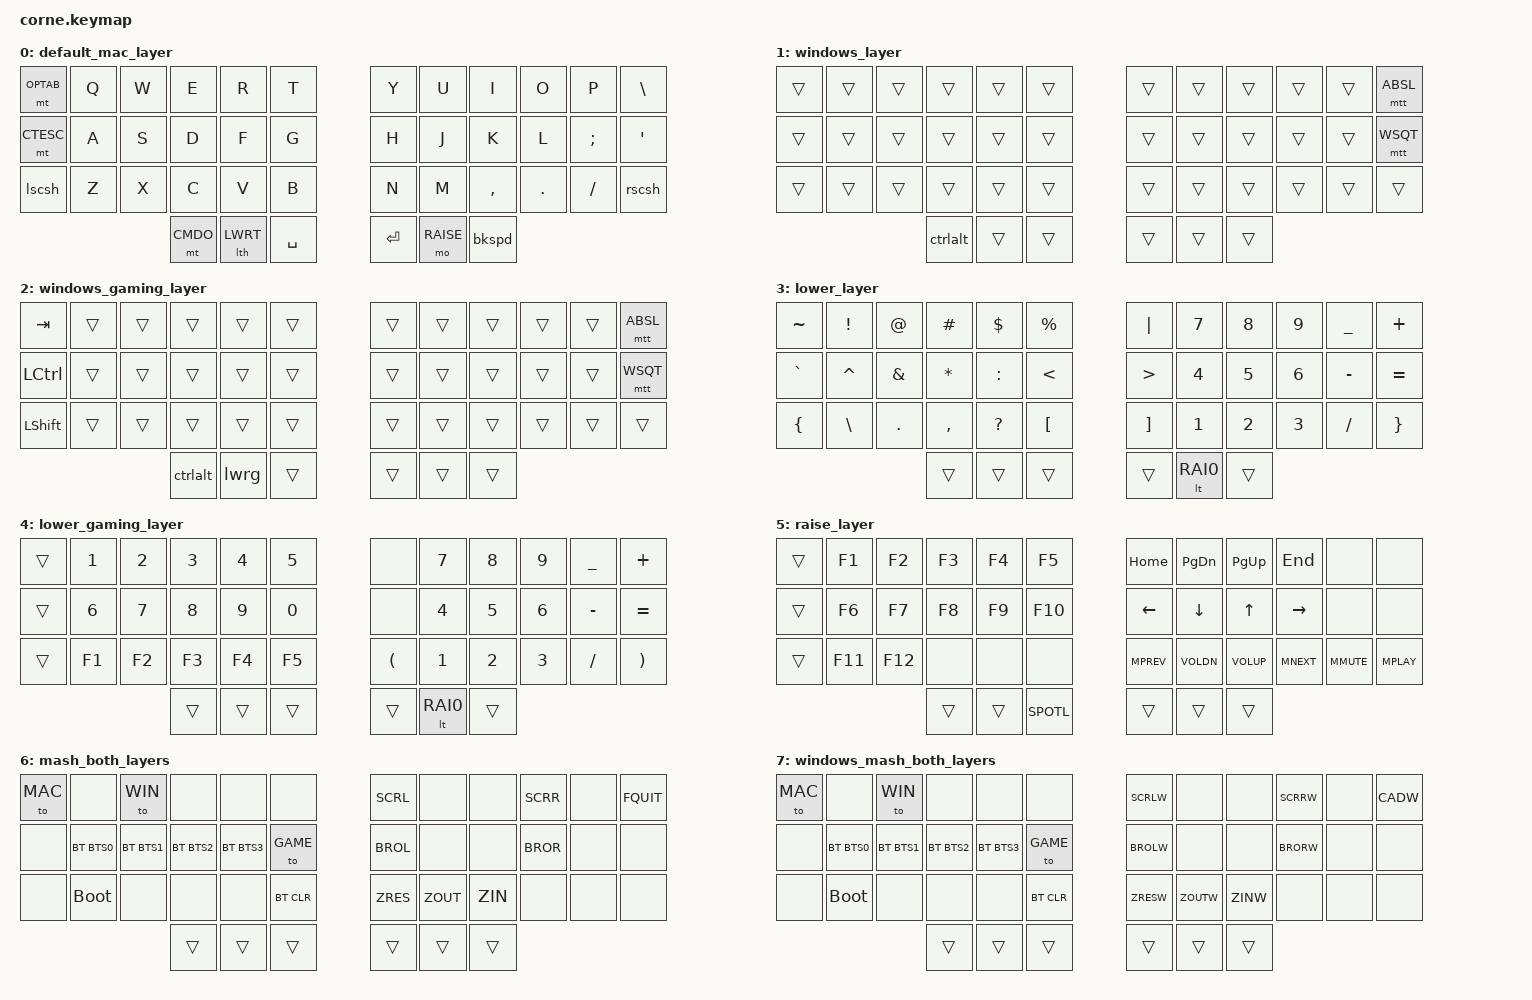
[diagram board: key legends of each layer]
#include <behaviors.dtsi>
#include <dt-bindings/zmk/keys.h>
#include <dt-bindings/zmk/bt.h>

// Layers
#define MAC 0
#define WIN 1
#define GAME 2
#define LOWER 3
#define GAME_LOWER 4
#define RAISE 5
#define MASH 6
#define WIN_MASH 7

// Aliases
#define OPTAB LALT TAB       // Mod-Tap shorthand for OPTION when held, TAB when tapped
#define CTESC LCTRL ESC      // Mod-Tap shorthand for CTRL when held, ESC when tapped
#define LWRT  LOWER F13      // Hold for lower layer, tap for app launcher modal
#define CMDO  LGUI F14       // Hold for cmd, tap for macros modal
#define RAI0  RAISE N0       // Mod-Tap shorthand for RAISE layer when held, or numpad 0 when typed
#define SPOTL LG(SPACE)      // Key-Press shorthand for CMD-SPACE Spotlight / Raycast / etc. search
#define MPREV C_PREV         // Key-Press shorthand for PREV media key
#define MNEXT C_NEXT         // Key-Press shorthand for NEXT media key
#define VOLUP C_VOL_UP       // Key-Press shorthand for VOLUME UP media key
#define VOLDN C_VOL_DN       // Key-Press shorthand for VOLUME DOWN media key
#define MPLAY C_PP           // Key-Press shorthand for PLAY / PAUSE media key
#define MMUTE C_MUTE         // Key-Press shorthand for MUTE media key
#define SCRL  LC(LEFT)       // Key-Press shorthand for Mission control space left
#define SCRR  LC(RIGHT)      // Key-Press shorthand for Mission control space right
#define BROL  LG(LA(LEFT))   // Key-Press shorthand for browser tab left
#define BROR  LG(LA(RIGHT))  // Key-Press shorthand for browser tab right
#define ZIN   LG(EQUAL)      // Key-Press shorthand for zoom in
#define ZOUT  LG(MINUS)      // Key-Press shorthand for zoom out
#define ZRES  LG(N0)         // Key-Press shorthand for zoom reset
#define FQUIT LG(LA(ESC))    // Key-Press shorthand for force quit applications dialog
#define BTS0  BT_SEL 0       // Select Bluetooth profile 0
#define BTS1  BT_SEL 1       // Select Bluetooth profile 1
#define BTS2  BT_SEL 2       // Select Bluetooth profile 2
#define BTS3  BT_SEL 3       // Select Bluetooth profile 3

// Windows Specific Aliases
#define ABSL  LALT BSLH      // Mod-Tap shorthand for ALT when held, BSLH when tapped
#define WSQT  LGUI SQT       // Mod-Tap shorthand for WIN when held, SQT when tapped
#define SCRLW LG(LC(LEFT))   // Key-Press shorthand for virtual desktop left in Windows
#define SCRRW LG(LC(RIGHT))  // Key-Press shorthand for virtual desktop right in Windows
#define BROLW LC(LS(TAB))    // Key-Press shorthand for browser tab left in Windows
#define BRORW LC(TAB)        // Key-Press shorthand for browser tab right in Windows
#define ZINW  LC(EQUAL)      // Key-Press shorthand for zoom in Windows
#define ZOUTW LC(MINUS)      // Key-Press shorthand for zoom out in Windows
#define ZRESW LC(N0)         // Key-Press shorthand for zoom reset in Windows
#define CADW  LC(LA(DEL))    // Key-Press shorthand for CTRL-ALT-DEL in Windows

/ {

    keymap {
        compatible = "zmk,keymap";

        default_mac_layer {
            bindings = <
            // +----------+----------+----------+----------+----------+----------+     +----------+----------+----------+----------+--[ COMBO FOR DEL ]--+
            //   OPT TAB    Q          W          E          R          T                Y          U          I          O          P          \ |
                 &mt OPTAB  &kp Q      &kp W      &kp E      &kp R      &kp T            &kp Y      &kp U      &kp I      &kp O      &kp P      &kp BSLH
            // +----------+----------+--[ HYPER + BIG HYPER COMBOS ]--+----------+     +----------+----------+----------+----------+----------+----------+
            //   CTRL ESC   A          S          D          F          G                H          J          K          L          ; :        ' "
                 &mt CTESC  &kp A      &kp S      &kp D      &kp F      &kp G            &kp H      &kp J      &kp K      &kp L      &kp SEMI   &kp SQT
            // +----------+----------+----------+----------+----------+----------+     +----------+----------+----------+----------+----------+----------+
            //   SHIFT (    Z          X          C          V          B                N          M          , <        . >        / ?        SHIFT )
                 &lscsh     &kp Z      &kp X      &kp C      &kp V      &kp B            &kp N      &kp M      &kp COMMA  &kp DOT    &kp FSLH   &rscsh
            // +----------+----------+----------+----------+----------+----------+     +----------+----------+----------+----------+----------+----------+
            //                                    CMD        LOWER      SPACE            ENTER      RAISE      BKSP DEL
                                                  &mt CMDO   &lth LWRT  &kp SPACE        &kp ENTER  &mo RAISE  &bkspd
            //                                  +----------+----------+----------+     +----------+----------+----------+
            //
            // * Notes:
            //   - In standard CAPS key position, hold for CTRL, or tap for ESC
            //   - In standard TAB key position, hold for OPT, or tap for TAB
            //   - In standard SHIFT key positions, hold for SHIFT, or tap for open `(` and close `)` parentheses (left and right respectively)
            //   - Combo D+F keys for HYPER (CTRL+OPT+CMD)
            //   - Combo S+D+F keys for BIG HYPER (SHIFT+CTRL+OPT+CMD)
            //   - Combo P+\ in top right corner for forward DEL
            //   - Shift backspace for forward delete
            //   - See other layers for more:
            //     - LOWER layer for symbols, numpad, summon apps function, summon terminal function, run macros function, etc.
            //     - RAISE layer for hjkl arrows, page navigation keys, media keys, function keys, spotlight search, etc.
            //     - MASH layer (LOWER+RAISE) for default layer toggling, screen switching, browser tab switching, zoom helpers, etc.
            >;
        };

        windows_layer {
            bindings = <
            // +----------+----------+----------+----------+----------+----------+     +----------+----------+----------+----------+---------------------+
            //                                                                                                                                  ALT \ |
                 &trans     &trans     &trans     &trans     &trans     &trans           &trans     &trans     &trans     &trans     &trans     &mtt ABSL
            // +----------+----------+----------+----------+----------+----------+     +----------+----------+----------+----------+---------------------+
            //                                                                                                                                  WIN ' "
                 &trans     &trans     &trans     &trans     &trans     &trans           &trans     &trans     &trans     &trans     &trans     &mtt WSQT
            // +----------+----------+----------+----------+----------+----------+     +----------+----------+----------+----------+----------+----------+
            //
                 &trans     &trans     &trans     &trans     &trans     &trans           &trans     &trans     &trans     &trans     &trans     &trans
            // +----------+----------+----------+----------+----------+----------+     +----------+----------+----------+----------+----------+----------+
            //                                    CTRL TAP
                                                  &ctrlalt   &trans     &trans           &trans     &trans     &trans
            //                                  +----------+----------+----------+     +----------+----------+----------+
            //
            // * Differences from above default Mac layer:
            //   - CTRL instead of CMD on thumb for easy copy/paste/etc. in Windows
            //   - CTRL thumb tap-dance for easy access to ALT, when right hand is on mouse
            //     - Tap once for CTRL
            //     - Tap twice for ALT
            //   - In standard backslash position, hold for ALT, or tap for `\`
            //   - In standard quote position, hold for WIN, or tap for `'`
            >;
        };

        windows_gaming_layer {
            bindings = <
            // +--[ COMBO FOR ESC ]--+----------+----------+----------+----------+     +----------+----------+----------+----------+---------------------+
            //   TAB                                                                                                                            ALT \ |
                 &kp TAB    &trans     &trans     &trans     &trans     &trans           &trans     &trans     &trans     &trans     &trans     &mtt ABSL
            // +----------+----------+----------+----------+----------+----------+     +----------+----------+----------+----------+---------------------+
            //   CTRL                                                                                                                           WIN ' "
                 &kp LCTRL  &trans     &trans     &trans     &trans     &trans           &trans     &trans     &trans     &trans     &trans     &mtt WSQT
            // +----------+----------+----------+----------+----------+----------+     +----------+----------+----------+----------+----------+----------+
            //   SHIFT
                 &kp LSHFT  &trans     &trans     &trans     &trans     &trans           &trans     &trans     &trans     &trans     &trans     &trans
            // +----------+----------+----------+----------+----------+----------+     +----------+----------+----------+----------+----------+----------+
            //                                    CTRL TAP   LOWER GAMING
                                                  &ctrlalt   &lwrg       &trans           &trans     &trans     &trans
            //                                  +----------+----------+----------+     +----------+----------+----------+
            //
            // * Differences from default Windows layer:
            //   - Combo TAB+Q in top left corner for easy access to ESC while gaming
            //   - Remove mod-tap and space cadet shift magic in left-most column, so that they don't interfere with gaming
            //   - See other layers for more:
            //     - Lower layer is customized for gaming, with access to numbers and function keys on left split
            //     - Touble tap and hold for access to normal symbols lower layer
            >;
        };

        lower_layer {
            bindings = <
            // +----------+----------+----------+----------+----------+----------+     +----------+----------+----------+----------+----------+----------+
            //   ~          !          @          #          $          %                |          7          8          9          _          +
                 &kp TILDE  &kp EXCL   &kp AT     &kp HASH   &kp DLLR   &kp PRCNT        &kp PIPE   &kp N7     &kp N8     &kp N9     &kp UNDER  &kp PLUS
            // +----------+----------+----------+----------+----------+----------+     +----------+----------+----------+----------+----------+----------+
            //   `          ^          &          *          :          <                >          4          5          6          -          =
                 &kp GRAVE  &kp CARET  &kp AMPS   &kp ASTRK  &kp COLON  &kp LT           &kp GT     &kp N4     &kp N5     &kp N6     &kp MINUS  &kp EQUAL
            // +----------+----------+----------+----------+----------+----------+     +----------+----------+----------+----------+----------+----------+
            //   {          \          .          ,          ?          [                ]          1          2          3          /          }
                 &kp LBRC   &kp BSLH   &kp DOT    &kp COMMA  &kp QMARK  &kp LBKT         &kp RBKT   &kp N1     &kp N2     &kp N3     &kp FSLH   &kp RBRC
            // +----------+----------+----------+----------+----------+----------+     +----------+----------+----------+----------+----------+----------+
            //                                                                                      0 RAISE
                                                  &trans     &trans     &trans           &trans     &lt RAI0   &trans
            //                                  +----------+----------+----------+     +----------+----------+----------+
            //
            // * Notes:
            //   - Almost all symbols accessible on this layer
            //   - Numpad under right hand
            >;
        };

        lower_gaming_layer {
            bindings = <
            // +----------+----------+----------+----------+----------+----------+     +----------+----------+----------+----------+----------+----------+
            //              1          2          3          4          5                           7          8          9          _          +
                 &trans     &kp N1     &kp N2     &kp N3     &kp N4     &kp N5           &none      &kp N7     &kp N8     &kp N9     &kp UNDER  &kp PLUS
            // +----------+----------+----------+----------+----------+----------+    +----------+----------+----------+----------+----------+----------+
            //              6          7          8          9          0                           4          5          6          -          =
                 &trans     &kp N6     &kp N7     &kp N8     &kp N9     &kp N0           &none      &kp N4     &kp N5     &kp N6     &kp MINUS  &kp EQUAL
            // +----------+----------+----------+----------+----------+----------+     +----------+----------+----------+----------+----------+----------+
            //              F1         F2         F3         F4         F5               (          1          2          3          /          )
                 &trans     &kp F1     &kp F2     &kp F3     &kp F4     &kp F5           &kp LPAR   &kp N1     &kp N2     &kp N3     &kp FSLH   &kp RPAR
            // +----------+----------+----------+----------+----------+----------+     +----------+----------+----------+----------+----------+----------+
            //                                                                                      0 RAISE
                                                  &trans     &trans     &trans           &trans     &lt RAI0   &trans
            //                                  +----------+----------+----------+     +----------+----------+----------+
            //
            // * Notes:
            //     - Basically same as standard lower layer, but with access to numbers and function keys on left split
            //       - But I left numpad on right split, since it doesn't hurt anybody to be there
            //     - For typing normal symbols layer while gaming, double tap and hold lower layer thumb
            //       - Though I moved left opening `(` paren to right split, since it's nowhere to be found on standard symbols layer
            >;
        };

        raise_layer {
            bindings = <
            // +----------+----------+----------+----------+----------+----------+     +----------+----------+----------+----------+----------+----------+
            //              FUNCTION KEYS 1-5                                            PAGE NAVIGATION
                 &trans     &kp F1     &kp F2     &kp F3     &kp F4     &kp F5           &kp HOME   &kp PG_DN  &kp PG_UP  &kp END    &none      &none
            // +----------+----------+----------+----------+----------+----------+     +----------+----------+----------+----------+----------+----------+
            //              FUNCTION KEYS 6-10                                           HJKL ARROW KEYS
                 &trans     &kp F6     &kp F7     &kp F8     &kp F9     &kp F10          &kp LEFT   &kp DOWN   &kp UP     &kp RIGHT  &none      &none
            // +----------+----------+----------+----------+----------+----------+     +----------+----------+----------+----------+----------+----------+
            //              FUNCTION KEYS 11-12                                          MEDIA KEYS
                 &trans     &kp F11    &kp F12    &none      &none      &none            &kp MPREV  &kp VOLDN  &kp VOLUP  &kp MNEXT  &kp MMUTE  &kp MPLAY
            // +----------+----------+----------+----------+----------+----------+     +----------+----------+----------+----------+----------+----------+
            //                                                          SEARCH
                                                  &trans     &trans     &kp SPOTL        &trans     &trans     &trans
            //                                  +----------+----------+----------+     +----------+----------+----------+
            //
            // * Notes:
            //   - Arrow keys in HJKL position
            //   - Page navigation (HOME, PG DOWN, PG UP, END) in HJKL-like position, but up one row
            //   - Media keys (PREV, VOL DOWN, VOL UP, NEXT, etc.) in HJKL-like position, but down one row
            //     - These are intentionally on raise layer so that you can play/pause/mute with one hand while on phone, etc.
            //   - Function keys on left split
            //   - Spotlight search on SPACE key
            >;
        };

        mash_both_layers {
            bindings = <
            // +----------+----------+----------+----------+----------+----------+     +----------+----------+----------+----------+----------+----------+
            //  MAC LAYER              WINDOWS LAYER                                     SCREEN SWITCHING                                      FORCE QUIT
                &to MAC    &none       &to WIN    &none      &none      &none            &kp SCRL   &none      &none      &kp SCRR   &none      &kp FQUIT
            // +----------+----------+----------+----------+----------+----------+     +----------+----------+----------+----------+----------+----------+
            //             BLUETOOTH PROFILES                        GAMING LAYER        BROWSER TAB SWITCHING
                 &none     &bt BTS0    &bt BTS1   &bt BTS2   &bt BTS3    &to GAME        &kp BROL   &none      &none      &kp BROR   &none      &none
            // +----------+----------+----------+----------+----------+----------+     +----------+----------+----------+----------+----------+----------+
            //             ZMK FLASH                              BLUETOOTH CLEAR        ZOOM IN, OUT, AND RESET
                 &none     &bootloader &none      &none      &none     &bt BT_CLR        &kp ZRES   &kp ZOUT   &kp ZIN    &none      &none      &none
            // +----------+----------+----------+----------+----------+----------+     +----------+----------+----------+----------+----------+----------+
            //
                                                  &trans     &trans     &trans           &trans     &trans     &trans
            //                                  +----------+----------+----------+     +----------+----------+----------+
            //
            // * Notes:
            //   - Many call this the ADJUST layer, but we're calling it MASH because you mash both LOWER + RAISE keys
            //   - Hit top left key to toggle default Mac layer
            //   - Hit `W` position to toggle Windows layer
            //   - Hit `G` position to toggle Windows Gaming layer
            //   - Hit `Z` position to put central half into ZMK bootloader mode for flashing keymap (can also double press central's reset switch)
            //   - HJKL-like screen switching, browser tab switching, and zoom in/out/reset helpers on right split
            //   - Hit top right key to open Mac's `Force Quit Applications` dialog
            >;
        };

        windows_mash_both_layers {
            bindings = <
            // +----------+----------+----------+----------+----------+----------+     +----------+----------+----------+----------+----------+----------+
            //  MAC LAYER              WINDOWS LAYER                                     SCREEN SWITCHING                                    CTRL+ALT+DEL
                &to MAC     &none      &to WIN    &none      &none      &none            &kp SCRLW  &none      &none      &kp SCRRW  &none      &kp CADW
            // +----------+----------+----------+----------+----------+----------+     +----------+----------+----------+----------+----------+----------+
            //             BLUETOOTH PROFILES                        GAMING LAYER        BROWSER TAB SWITCHING
                 &none     &bt BTS0    &bt BTS1   &bt BTS2   &bt BTS3    &to GAME        &kp BROLW  &none      &none      &kp BRORW  &none      &none
            // +----------+----------+----------+----------+----------+----------+     +----------+----------+----------+----------+----------+----------+
            //             ZMK FLASH                              BLUETOOTH CLEAR        ZOOM IN, OUT, AND RESET
                 &none     &bootloader &none      &none      &none     &bt BT_CLR        &kp ZRESW  &kp ZOUTW  &kp ZINW   &none      &none      &none
            // +----------+----------+----------+----------+----------+----------+     +----------+----------+----------+----------+----------+----------+
            //
                                                  &trans     &trans     &trans           &trans     &trans     &trans
            //                                  +----------+----------+----------+     +----------+----------+----------+
            //
            // * Differences from above MASH layer:
            //   - HJKL-like screen switching hotkeys are adjusted to work in Windows
            //   - Hit top right key to CTRL+ALT+DELETE in Windows
            >;
        };

    };

    conditional_layers {
        compatible = "zmk,conditional-layers";
        mash_both_layers {
            if-layers = <LOWER RAISE>;
            then-layer = <MASH>;
        };
        windows_mash_both_layers {
            if-layers = <WIN LOWER RAISE>;
            then-layer = <WIN_MASH>;
        };
        windows_gaming_mash_both_layers {
            if-layers = <GAME GAME_LOWER RAISE>;
            then-layer = <WIN_MASH>;
        };
    };

    behaviors {
        mtt: mod_tap_with_tap_preferred {
            compatible = "zmk,behavior-hold-tap";
            #binding-cells = <2>;
            tapping-term-ms = <200>;
            flavor = "tap-preferred";
            bindings = <&kp>, <&kp>;
        };

        lscsh: left_space_cadet_shift {
            compatible = "zmk,behavior-mod-morph";
            #binding-cells = <0>;
            bindings = <&mt LSHFT LPAR>, <&close_and_open_parens>;
            mods = <(MOD_RSFT)>;
        };

        rscsh: right_space_cadet_shift {
            compatible = "zmk,behavior-mod-morph";
            #binding-cells = <0>;
            bindings = <&mt RSHFT RPAR>, <&open_and_close_parens>;
            mods = <(MOD_LSFT)>;
        };

        bkspd: backspace_or_shift_delete {
            compatible = "zmk,behavior-mod-morph";
            #binding-cells = <0>;
            bindings = <&kp BACKSPACE>, <&kp DELETE>;
            mods = <(MOD_LSFT)>;
        };

        lth: layer_tap_hold_preferred {
            compatible = "zmk,behavior-hold-tap";
            #binding-cells = <2>;
            tapping-term-ms = <150>;
            flavor = "hold-preferred";
            bindings = <&mo>, <&kp>;
        };

        ctrlalt: ctrl_alt_tap_dance_for_gaming {
            compatible = "zmk,behavior-tap-dance";
            #binding-cells = <0>;
            tapping-term-ms = <250>;
            bindings = <&kp LCTRL>, <&kp LALT>;
        };

        lwrg: lower_layer_tap_dance_for_gaming {
            compatible = "zmk,behavior-tap-dance";
            #binding-cells = <0>;
            tapping-term-ms = <250>;
            bindings = <&mo GAME_LOWER>, <&mo LOWER>;
        };
    };

    macros {
        open_and_close_parens: open_and_close_parens {
            compatible = "zmk,behavior-macro";
            #binding-cells = <0>;
            bindings = <&macro_tap &kp LPAR &kp RPAR>;
        };

        close_and_open_parens: close_and_open_parens {
            compatible = "zmk,behavior-macro";
            #binding-cells = <0>;
            bindings = <&macro_tap &kp RPAR &kp LPAR>;
        };
    };

    combos {
        compatible = "zmk,combos";
        combo_hyper {
            timeout-ms = <50>;
            key-positions = <15 16>;
            bindings = <&kp LG(LA(LCTRL))>;
        };
        combo_big_hyper {
            timeout-ms = <50>;
            key-positions = <14 15 16>;
            bindings = <&kp LS(LG(LA(LCTRL)))>;
        };
        combo_del_in_top_right_corner {
            timeout-ms = <50>;
            key-positions = <10 11>;
            bindings = <&kp DEL>;
        };
        combo_esc_in_top_left_corner_for_gaming {
            timeout-ms = <50>;
            key-positions = <0 1>;
            bindings = <&kp ESC>;
            layers = <GAME>;
        };
    };

};
